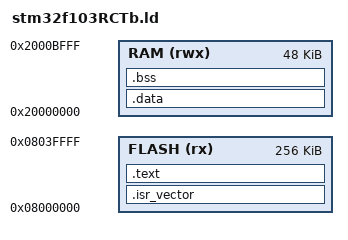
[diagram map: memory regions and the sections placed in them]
/* STM32F103RCTb */
MEMORY
{
  FLASH (rx) : ORIGIN = 0x08000000, LENGTH = 256K
  RAM  (rwx) : ORIGIN = 0x20000000, LENGTH = 48K
}

_estack = ORIGIN(RAM) + LENGTH(RAM);

SECTIONS
{
  .isr_vector :
  {
    KEEP(*(.isr_vector))
  } > FLASH

  .text :
  {
    *(.text*)
    *(.rodata*)
    _etext = .;
  } > FLASH

  .data : AT (ADDR(.text) + SIZEOF(.text))
  {
    _sdata = .;
    *(.data*)
    _edata = .;
  } > RAM

  .bss :
  {
    _sbss = .;
    *(.bss*)
    _ebss = .;
  } > RAM
}
